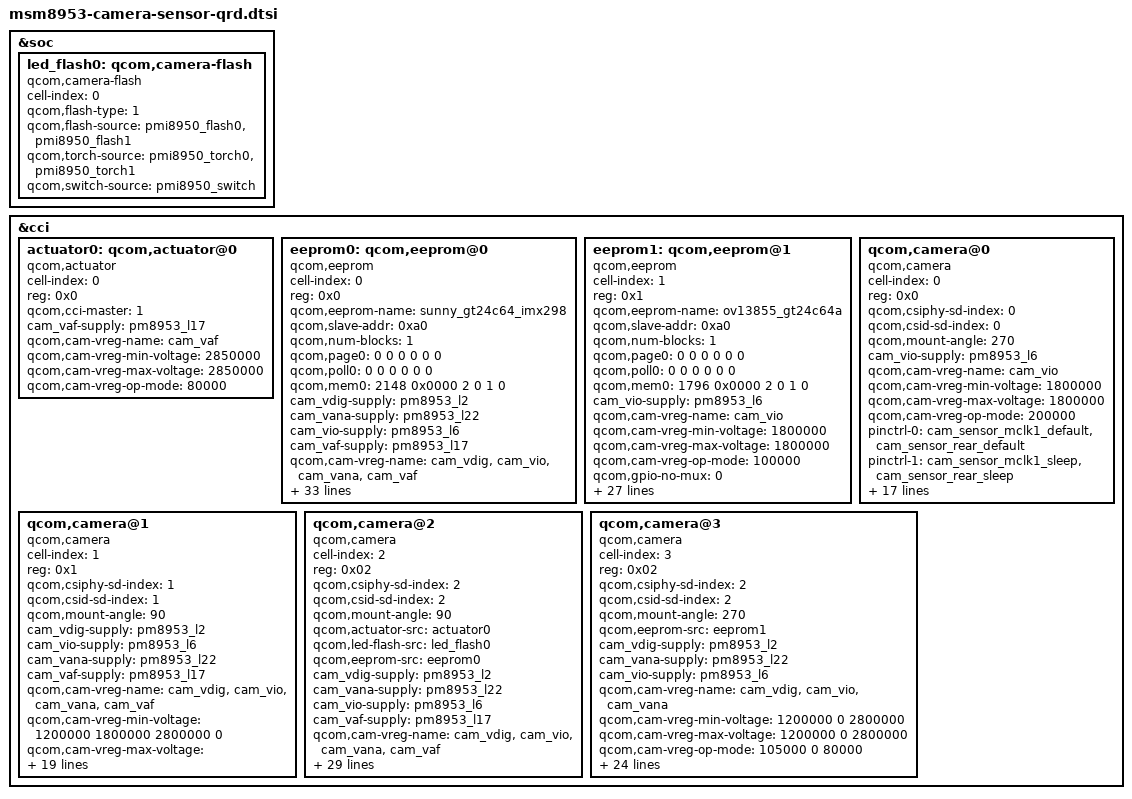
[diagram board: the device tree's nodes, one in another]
/*
 * Copyright (c) 2015-2016, The Linux Foundation. All rights reserved.
 *
 * This program is free software; you can redistribute it and/or modify
 * it under the terms of the GNU General Public License version 2 and
 * only version 2 as published by the Free Software Foundation.
 *
 * This program is distributed in the hope that it will be useful,
 * but WITHOUT ANY WARRANTY; without even the implied warranty of
 * MERCHANTABILITY or FITNESS FOR A PARTICULAR PURPOSE.  See the
 * GNU General Public License for more details.
 */
#include "msm-pmi8950.dtsi"
&soc {
	led_flash0: qcom,camera-flash {
		cell-index = <0>;
		compatible = "qcom,camera-flash";
		qcom,flash-type = <1>;
		qcom,flash-source = <&pmi8950_flash0 &pmi8950_flash1>;
		qcom,torch-source = <&pmi8950_torch0 &pmi8950_torch1>;
		qcom,switch-source = <&pmi8950_switch>;
	};
};

&cci {

	actuator0: qcom,actuator@0 {
		cell-index = <0>;
		reg = <0x0>;
		compatible = "qcom,actuator";
		qcom,cci-master = <1>;
		cam_vaf-supply = <&pm8953_l17>;
		qcom,cam-vreg-name = "cam_vaf";
		qcom,cam-vreg-min-voltage = <2850000>;
		qcom,cam-vreg-max-voltage = <2850000>;
		qcom,cam-vreg-op-mode = <80000>;
	};

        eeprom0: qcom,eeprom@0 {
		cell-index = <0>;
		compatible = "qcom,eeprom";
		reg = <0x0>;
		qcom,eeprom-name = "sunny_gt24c64_imx298";
		qcom,slave-addr = <0xa0>;
                qcom,num-blocks = <1>;
		qcom,page0 = <0 0 0 0 0 0>;
		qcom,poll0 = <0 0 0 0 0 0>;
		qcom,mem0 = <2148 0x0000 2 0 1 0>;
		cam_vdig-supply = <&pm8953_l2>;
		cam_vana-supply = <&pm8953_l22>;
		cam_vio-supply = <&pm8953_l6>;
		cam_vaf-supply = <&pm8953_l17>;
		qcom,cam-vreg-name = "cam_vdig", "cam_vio", "cam_vana","cam_vaf";
		qcom,cam-vreg-min-voltage = <1200000 1800000 2500000 2850000>;
		qcom,cam-vreg-max-voltage = <1200000 1800000 2500000 2850000>;
		qcom,cam-vreg-op-mode = <105000 100000 80000 100000>;
		qcom,gpio-no-mux = <0>;
		pinctrl-names = "cam_default", "cam_suspend";
		pinctrl-0 = <&cam_sensor_mclk2_default
				&cam_sensor_back_default>;
		pinctrl-1 = <&cam_sensor_mclk2_sleep
				&cam_sensor_back_sleep>;
		gpios = <&tlmm 28 0>,
			<&tlmm 131 0>,
			<&tlmm 130 0>,
			<&tlmm 96 0>,
			<&tlmm 97 0>,
			<&tlmm 41 0>;
		qcom,gpio-reset = <1>;
		qcom,gpio-standby = <2>;
		qcom,gpio-custom1 = <3>;
		qcom,gpio-custom2 = <4>;
		qcom,gpio-af-pwdm = <5>;
		qcom,gpio-req-tbl-num = <0 1 2 3 4 5>;
		qcom,gpio-req-tbl-flags = <1 0 0 0 0 0>;
		qcom,gpio-req-tbl-label = "CAMIF_MCLK2",
					  "CAM_RESET2",
					  "CAM_STANDBY2",
					  "CAM_CUSTOM1",
					  "CAM_CUSTOM2",
					  "CAM_AFPWDM";
		qcom,cam-power-seq-type = "sensor_vreg","sensor_vreg","sensor_vreg", "sensor_clk";
		qcom,cam-power-seq-val = "cam_vdig", "cam_vio", "cam_vana","sensor_cam_mclk";
		qcom,cam-power-seq-cfg-val = <1 1 1 24000000>;
		qcom,cam-power-seq-delay = <1 1 1 30>;
		qcom,cci-master = <1>;
		status = "ok";
		clocks = <&clock_gcc clk_mclk2_clk_src>,
			<&clock_gcc clk_gcc_camss_mclk2_clk>;
		clock-names = "cam_src_clk", "cam_clk";
		qcom,clock-rates = <24000000 0>;
	};

        eeprom1: qcom,eeprom@1 {
		cell-index = <1>;
		compatible = "qcom,eeprom";
		reg = <0x1>;
		qcom,eeprom-name = "ov13855_gt24c64a";
		qcom,slave-addr = <0xa0>;
                qcom,num-blocks = <1>;
		qcom,page0 = <0 0 0 0 0 0>;
		qcom,poll0 = <0 0 0 0 0 0>;
		qcom,mem0 = <1796 0x0000 2 0 1 0>;
		cam_vio-supply = <&pm8953_l6>;
		qcom,cam-vreg-name = "cam_vio";
		qcom,cam-vreg-min-voltage = <1800000>;
		qcom,cam-vreg-max-voltage = <1800000>;
		qcom,cam-vreg-op-mode = <100000>;
		qcom,gpio-no-mux = <0>;
		pinctrl-names = "cam_default", "cam_suspend";
		pinctrl-0 = <&cam_sensor_mclk3_default
				&cam_sensor_front2_default>;
		pinctrl-1 = <&cam_sensor_mclk3_sleep
				&cam_sensor_front2_sleep>;
		gpios = <&tlmm 128 0>,
			<&tlmm 129 0>,
			<&tlmm 46 0>,
			<&tlmm 96 0>,
			<&tlmm 97 0>,
			<&tlmm 0 0>,
			<&tlmm 1 0>;
		qcom,gpio-reset = <1>;
		qcom,gpio-standby = <2>;
		qcom,gpio-custom1 = <3>;
		qcom,gpio-custom2 = <4>;
		qcom,gpio-custom3 = <5>;
		qcom,gpio-custom4 = <6>;
		qcom,gpio-req-tbl-num = <0 1 2 3 4 5 6>;
		qcom,gpio-req-tbl-flags = <1 0 0 0 0 0 0>;
		qcom,gpio-req-tbl-label = "CAMIF_MCLK3",
					  "CAM_RESET3",
					  "CAM_STANDBY3",
					  "CAM_CUSTOM1",
					  "CAM_CUSTOM2",
					  "CAM_CUSTOM3",
					  "CAM_CUSTOM4";
		qcom,cam-power-seq-type = "sensor_vreg", "sensor_clk";
		qcom,cam-power-seq-val = "cam_vio","sensor_cam_mclk";
		qcom,cam-power-seq-cfg-val = <1 24000000>;
		qcom,cam-power-seq-delay = <1 30>;
		qcom,cci-master = <0>;
		status = "ok";
		clocks = <&clock_gcc clk_mclk3_clk_src>,
			<&clock_gcc clk_gcc_camss_mclk3_clk>;
		clock-names = "cam_src_clk", "cam_clk";
		qcom,clock-rates = <24000000 0>;

	};
/*
	eeprom0: qcom,eeprom@0 {
		cell-index = <0>;
		compatible = "qcom,eeprom";
		qcom,cci-master = <0>;
		reg = <0x0>;
		cam_vio-supply = <&pm8953_l6>;
		cam_vdig-supply = <&pm8953_l2>;
		cam_vaf-supply = <&pm8953_l17>;
		qcom,cam-vreg-name = "cam_vio", "cam_vdig", "cam_vaf";
		qcom,cam-vreg-min-voltage = <0 1100000 2850000>;
		qcom,cam-vreg-max-voltage = <0 1100000 2850000>;
		qcom,cam-vreg-op-mode = <0 105000 100000>;
		pinctrl-names = "cam_default", "cam_suspend";
		pinctrl-0 = <&cam_sensor_mclk0_default
						&cam_sensor_rear_default>;
		pinctrl-1 = <&cam_sensor_mclk0_sleep &cam_sensor_rear_sleep>;
		gpios = <&tlmm 26 0>,
			<&tlmm 40 0>,
			<&tlmm 39 0>;
		qcom,gpio-reset = <1>;
		qcom,gpio-standby = <2>;
		qcom,gpio-req-tbl-num = <0 1 2>;
		qcom,gpio-req-tbl-flags = <1 0 0>;
		qcom,gpio-req-tbl-label = "CAMIF_MCLK0",
			"CAM_RESET0",
			"CAM_STANDBY0";
		status = "ok";
		clocks = <&clock_gcc clk_mclk0_clk_src>,
				<&clock_gcc clk_gcc_camss_mclk0_clk>;
		clock-names = "cam_src_clk", "cam_clk";
		qcom,clock-rates = <19200000 0>;
	};

	eeprom2: qcom,eeprom@2 {
		cell-index = <2>;
		reg = <0x2>;
		compatible = "qcom,eeprom";
		qcom,cci-master = <1>;
		cam_vdig-supply = <&pm8953_l23>;
		cam_vana-supply = <&pm8953_l22>;
		cam_vio-supply = <&pm8953_l6>;
		qcom,cam-vreg-name = "cam_vdig", "cam_vio", "cam_vana";
		qcom,cam-vreg-min-voltage = <1200000 0 2800000>;
		qcom,cam-vreg-max-voltage = <1200000 0 2800000>;
		qcom,cam-vreg-op-mode = <105000 0 80000>;
		qcom,gpio-no-mux = <0>;
		pinctrl-names = "cam_default", "cam_suspend";
		pinctrl-0 = <&cam_sensor_mclk1_default
						&cam_sensor_front1_default>;
		pinctrl-1 = <&cam_sensor_mclk1_sleep &cam_sensor_front1_sleep>;
		gpios = <&tlmm 27 0>,
			<&tlmm 129 0>,
			<&tlmm 130 0>;
		qcom,gpio-reset = <1>;
		qcom,gpio-standby = <2>;
		qcom,gpio-req-tbl-num = <0 1 2>;
		qcom,gpio-req-tbl-flags = <1 0 0>;
		qcom,gpio-req-tbl-label = "CAMIF_MCLK2",
					  "CAM_RESET2",
					  "CAM_STANDBY2";
		qcom,sensor-mode = <0>;
		status = "ok";
		clocks = <&clock_gcc clk_mclk1_clk_src>,
			<&clock_gcc clk_gcc_camss_mclk1_clk>;
		clock-names = "cam_src_clk", "cam_clk";
		qcom,clock-rates = <19200000 0>;
	};
*/

	qcom,camera@0 {
		cell-index = <0>;
		compatible = "qcom,camera";
		reg = <0x0>;
		qcom,csiphy-sd-index = <0>;
		qcom,csid-sd-index = <0>;
		qcom,mount-angle = <270>;
		//qcom,eeprom-src = <&eeprom0>;
		//qcom,actuator-src = <&actuator0>;
		//qcom,led-flash-src = <&led_flash0>;
		//cam_vdig-supply = <&pm8953_l2>;
		cam_vio-supply = <&pm8953_l6>;
		//cam_vana-supply = <&pm8953_l22>;
		qcom,cam-vreg-name =  "cam_vio";
		qcom,cam-vreg-min-voltage = < 1800000 >;
		qcom,cam-vreg-max-voltage = < 1800000 >;
		qcom,cam-vreg-op-mode = < 200000 >;
		pinctrl-names = "cam_default", "cam_suspend";
		pinctrl-0 = <&cam_sensor_mclk1_default
				&cam_sensor_rear_default>;
		pinctrl-1 = <&cam_sensor_mclk1_sleep
				&cam_sensor_rear_sleep>;
		gpios = <&tlmm 27 0>,
                        <&tlmm 132 0>,
                        <&tlmm 95 0>,
			<&tlmm 36 0>,
			<&tlmm 39 0>;
		qcom,gpio-reset = <1>;
		qcom,gpio-standby = <2>;
                qcom,gpio-vdig = <3>;
                qcom,gpio-vana = <4>;
		qcom,gpio-req-tbl-num = <0 1 2 3 4 >;
		qcom,gpio-req-tbl-flags = <1 0 0 0 0>;
		qcom,gpio-req-tbl-label = "CAMIF_MCLK1",
			"CAM_RESET0",
			"CAM_STANDBY0",
                        "CAM_DVDD0",
                        "CAM_AVDD0";
		qcom,sensor-position = <0>;
		qcom,sensor-mode = <0>;
		qcom,cci-master = <0>;
		status = "ok";
		clocks = <&clock_gcc clk_mclk1_clk_src>,
			<&clock_gcc clk_gcc_camss_mclk1_clk>;
		clock-names = "cam_src_clk", "cam_clk";
		qcom,clock-rates = <24000000 0>;
	};
	qcom,camera@1 {
		cell-index = <1>;
		compatible = "qcom,camera";
		reg = <0x1>;
		qcom,csiphy-sd-index = <1>;
		qcom,csid-sd-index = <1>;
		qcom,mount-angle = <90>;
		cam_vdig-supply = <&pm8953_l2>;
		cam_vio-supply = <&pm8953_l6>;
		cam_vana-supply = <&pm8953_l22>;
		cam_vaf-supply = <&pm8953_l17>;
		qcom,cam-vreg-name = "cam_vdig", "cam_vio", "cam_vana",
							"cam_vaf";
		qcom,cam-vreg-min-voltage = <1200000 1800000 2800000 0>;
		qcom,cam-vreg-max-voltage = <1200000 1800000 2800000 0>;
		qcom,cam-vreg-op-mode = <200000 200000 80000 0>;
		pinctrl-names = "cam_default", "cam_suspend";
		pinctrl-0 = <&cam_sensor_mclk0_default
				&cam_sensor_front_default>;
		pinctrl-1 = <&cam_sensor_mclk0_sleep
				&cam_sensor_front_sleep>;
		gpios = <&tlmm 26 0>,
			<&tlmm 93 0>,
			<&tlmm 94 0>;
		qcom,gpio-reset = <1>;
		qcom,gpio-standby = <2>;
		qcom,gpio-req-tbl-num = <0 1 2>;
		qcom,gpio-req-tbl-flags = <1 0 0>;
		qcom,gpio-req-tbl-label = "CAMIF_MCLK0",
			"CAM_RESET1",
			"CAM_STANDBY1";
		qcom,sensor-position = <1>;
		qcom,sensor-mode = <0>;
		qcom,cci-master = <1>;
		status = "ok";
		clocks = <&clock_gcc clk_mclk0_clk_src>,
				<&clock_gcc clk_gcc_camss_mclk0_clk>;
		clock-names = "cam_src_clk", "cam_clk";
		qcom,clock-rates = <24000000 0>;
	};

	qcom,camera@2 {
		cell-index = <2>;
		compatible = "qcom,camera";
		reg = <0x02>;
		qcom,csiphy-sd-index = <2>;
		qcom,csid-sd-index = <2>;
		qcom,mount-angle = <90>;
		qcom,actuator-src = <&actuator0>;
		qcom,led-flash-src = <&led_flash0>;
		qcom,eeprom-src = <&eeprom0>;
		cam_vdig-supply = <&pm8953_l2>;
		cam_vana-supply = <&pm8953_l22>;
		cam_vio-supply = <&pm8953_l6>;
		cam_vaf-supply = <&pm8953_l17>;
		qcom,cam-vreg-name = "cam_vdig", "cam_vio", "cam_vana","cam_vaf";
		qcom,cam-vreg-min-voltage = <1200000 1800000 2500000 2850000>;
		qcom,cam-vreg-max-voltage = <1200000 1800000 2500000 2850000>;
		qcom,cam-vreg-op-mode = <105000 100000 80000 100000>;
		qcom,gpio-no-mux = <0>;
		pinctrl-names = "cam_default", "cam_suspend";
		pinctrl-0 = <&cam_sensor_mclk2_default
				&cam_sensor_back_default>;
		pinctrl-1 = <&cam_sensor_mclk2_sleep
				&cam_sensor_back_sleep>;
		gpios = <&tlmm 28 0>,
			<&tlmm 131 0>,
			<&tlmm 130 0>,
			<&tlmm 96 0>,
			<&tlmm 97 0>,
			<&tlmm 41 0>;
		qcom,gpio-reset = <1>;
		qcom,gpio-standby = <2>;
		qcom,gpio-custom1 = <3>;
		qcom,gpio-custom2 = <4>;
		qcom,gpio-af-pwdm = <5>;
		qcom,gpio-req-tbl-num = <0 1 2 3 4 5>;
		qcom,gpio-req-tbl-flags = <1 0 0 0 0 0>;
		qcom,gpio-req-tbl-label = "CAMIF_MCLK2",
					  "CAM_RESET2",
					  "CAM_STANDBY2",
					  "CAM_CUSTOM1",
					  "CAM_CUSTOM2",
					  "CAM_AFPWDM";
		qcom,sensor-position = <1>;
		qcom,sensor-mode = <0>;
		qcom,cci-master = <1>;
		status = "ok";
		clocks = <&clock_gcc clk_mclk2_clk_src>,
			<&clock_gcc clk_gcc_camss_mclk2_clk>;
		clock-names = "cam_src_clk", "cam_clk";
		qcom,clock-rates = <24000000 0>;
	};


	qcom,camera@3 {
		cell-index = <3>;
		compatible = "qcom,camera";
		reg = <0x02>;
		qcom,csiphy-sd-index = <2>;
		qcom,csid-sd-index = <2>;
		qcom,mount-angle = <270>;
		qcom,eeprom-src = <&eeprom1>;
		cam_vdig-supply = <&pm8953_l2>;
		cam_vana-supply = <&pm8953_l22>;
		cam_vio-supply = <&pm8953_l6>;
		qcom,cam-vreg-name = "cam_vdig", "cam_vio", "cam_vana";
		qcom,cam-vreg-min-voltage = <1200000 0 2800000>;
		qcom,cam-vreg-max-voltage = <1200000 0 2800000>;
		qcom,cam-vreg-op-mode = <105000 0 80000>;
		qcom,gpio-no-mux = <0>;
		pinctrl-names = "cam_default", "cam_suspend";
		pinctrl-0 = <&cam_sensor_mclk3_default
				&cam_sensor_front2_default>;
		pinctrl-1 = <&cam_sensor_mclk3_sleep
				&cam_sensor_front2_sleep>;
		gpios = <&tlmm 128 0>,
			<&tlmm 129 0>,
			<&tlmm 46 0>,
			<&tlmm 96 0>,
			<&tlmm 97 0>,
			<&tlmm 0 0>,
			<&tlmm 1 0>;
		qcom,gpio-reset = <1>;
		qcom,gpio-standby = <2>;
		qcom,gpio-custom1 = <3>;
		qcom,gpio-custom2 = <4>;
		qcom,gpio-custom3 = <5>;
		qcom,gpio-custom4 = <6>;
		qcom,gpio-req-tbl-num = <0 1 2 3 4 5 6>;
		qcom,gpio-req-tbl-flags = <1 0 0 0 0 0 0>;
		qcom,gpio-req-tbl-label = "CAMIF_MCLK3",
					  "CAM_RESET3",
					  "CAM_STANDBY3",
					  "CAM_CUSTOM1",
					  "CAM_CUSTOM2",
					  "CAM_CUSTOM3",
					  "CAM_CUSTOM4";
		qcom,sensor-position = <1>;
		qcom,sensor-mode = <0>;
		qcom,cci-master = <0>;
		status = "ok";
		clocks = <&clock_gcc clk_mclk3_clk_src>,
			<&clock_gcc clk_gcc_camss_mclk3_clk>;
		clock-names = "cam_src_clk", "cam_clk";
		qcom,clock-rates = <24000000 0>;
	};

};
